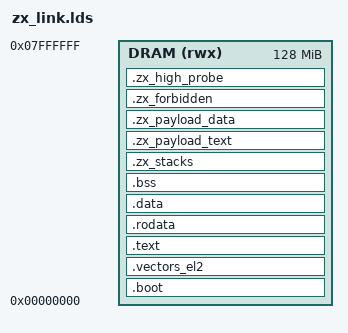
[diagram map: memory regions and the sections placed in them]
/***************************************************************************
 * Copyright (c) 2026 Eclipse ThreadX contributors
 *
 * This program and the accompanying materials are made available under the
 * terms of the MIT License which is available at
 * https://opensource.org/licenses/MIT.
 *
 * AI Disclosure: This file was largely AI-generated by Claude Code (Opus 5).
 * The AI-generated portions may be considered public domain (CC0-1.0)
 * and not subject to the project's licence. The human contributor has
 * reviewed and verified that the code is correct.
 *
 * SPDX-License-Identifier: MIT and CC0-1.0
 **************************************************************************/

/* Link map for the ZoneX stage-2 probe on the Armv8-R AEM FVP (BaseR).
 *
 * The BaseR memory map is the Base platform map with its two 2 GB halves
 * swapped: Base DRAM at 0x80000000 appears at 0x00000000 here, and the
 * 0x80000000-0xFFFFFFFF half holds peripherals and is execute-never in the
 * background map.  Code must therefore be linked into low DRAM; linking at
 * 0x80000000 produces a silent fault loop with no output.
 *
 * WHAT MAKES THIS SCRIPT DIFFERENT FROM AN ORDINARY BARE-METAL ONE
 *
 * Four areas below are not merely aligned but SIZED to whole 64-byte
 * granules, because each one is a stage-2 MPU region and PMSAv8-R has a
 * 64-byte granule with an inclusive limit:
 *
 *   .zx_payload_text   region 0, the payload's code
 *   .zx_payload_data   region 1, the payload's data
 *   .zx_forbidden      NO REGION AT ALL -- the whole point
 *   .zx_high_probe     region 16, the high-region experiment
 *
 * .zx_forbidden is placed IMMEDIATELY AFTER .zx_payload_data, adjacent by
 * construction.  An ungranted address far away from every grant proves only
 * that unmapped memory faults; the defect class worth catching is a region
 * whose limit or base is out by one granule, and only an adjacent hole
 * catches that.  Do not move it, and do not let anything land between it and
 * the payload's data.
 *
 * .zx_high_probe is placed after the hole rather than beside the payload,
 * because two enabled regions matching one address is CONSTRAINED
 * UNPREDICTABLE and aborts on the S32Z280.  Keeping region 16's granule well
 * clear of regions 0 and 1 makes the disjointness visible in the map file.
 *
 A NOTE ON ALIGN, because the two spellings are not equivalent
 *
 * Every ALIGN below is written AFTER the colon, which is the section's
 * ALIGNMENT.  Written before the colon it would be the section's ADDRESS,
 * evaluated from a location counter that starts at zero -- and it silently
 * overrides "> DRAM".  On this target that happens to be harmless because
 * DRAM starts at 0x00000000, which is precisely what makes it a trap: the
 * same script shape moved to the S32Z280, whose code SRAM starts at
 * 0x79900000, fails the link with "not within region" or, worse, places
 * sections somewhere plausible.  Keep both scripts in the safe form so that
 * neither teaches the wrong one.
 *
 * ZoneX's OWN code, data, bss and stack are covered by no region at all.
 * That is decision D2, not an oversight: with HSCTLR.BR=1 EL2's own accesses
 * fall back to the background map, while EL0/EL1 accesses that hit no region
 * fault regardless of BR -- so the hypervisor costs no region and is
 * protected from the payload precisely by not being mapped.
 */

ENTRY(_start)

__zx_hyp_stack_size = 0x1000;

MEMORY
{
    DRAM (rwx) : ORIGIN = 0x00000000, LENGTH = 0x08000000    /* 128 MB */
}

SECTIONS
{
    . = ALIGN(64);

    /* .text.boot first, so _start is at the front of the image.  It does not
       have to be at a fixed address on this target -- the model takes the
       entry point from the ELF -- but keeping the same section order as the
       silicon script, where it does, means one layout to reason about.  */

    .boot :
    {
        KEEP(*(.text.boot))
    } > DRAM

    .vectors_el2 :
    {
        KEEP(*(.vectors_el2))
    } > DRAM

    .text :
    {
        *(.text*)
        *(.glue_7)
        *(.glue_7t)
    } > DRAM

    .rodata :
    {
        . = ALIGN(4);
        *(.rodata*)
        . = ALIGN(4);
    } > DRAM

    .data : ALIGN(64)
    {
        __zx_data_start = .;
        *(.data*)
        . = ALIGN(4);
        __zx_data_end = .;
    } > DRAM

    .bss (NOLOAD) : ALIGN(64)
    {
        __zx_bss_start = .;
        *(.bss*)
        *(COMMON)
        . = ALIGN(4);
        __zx_bss_end = .;
    } > DRAM

    /* The hypervisor's Hyp-mode stack.  SP must stay 8-byte aligned
       (AAPCS), so the area is aligned before its top symbol is taken.  */

    .zx_stacks (NOLOAD) :
    {
        . = ALIGN(8);
        . = . + __zx_hyp_stack_size;
        __zx_hyp_stack_top = .;
    } > DRAM

    /* ------------------------------------------------------------------
       The partition areas.  Everything below is granule-aligned and
       granule-sized, and the ORDER of the last three is load-bearing.
       ------------------------------------------------------------------ */

    .zx_payload_text : ALIGN(64)
    {
        __zx_payload_code_start = .;
        KEEP(*(.zx_payload_text))
        . = ALIGN(64);
        __zx_payload_code_end = .;
    } > DRAM

    .zx_payload_data : ALIGN(64)
    {
        __zx_payload_data_start = .;
        KEEP(*(.zx_payload_data))
        . = ALIGN(64);
        __zx_payload_data_end = .;
    } > DRAM

    /* One granule, covered by NO region.  Adjacent to the payload's data by
       construction -- see the header.  */

    .zx_forbidden (NOLOAD) : ALIGN(64)
    {
        __zx_forbidden_start = .;
        . = . + 64;
        __zx_forbidden_end = .;
    } > DRAM

    .zx_high_probe : ALIGN(64)
    {
        __zx_high_probe_start = .;
        KEEP(*(.zx_high_probe))
        . = ALIGN(64);
        __zx_high_probe_end = .;
    } > DRAM

    . = ALIGN(8);
    _end = .;
    PROVIDE(end = .);

    /* Assert the geometry the region programming depends on, so that a
       layout mistake fails the LINK rather than the run.  A region whose
       base is under-aligned does not fault: its low bits land on SH, AP and
       XN and silently change the region's attributes, which is the single
       hardest failure in this architecture to see.  */

    ASSERT((__zx_payload_code_start & 63) == 0,
           "payload code region base is not 64-byte aligned")
    ASSERT((__zx_payload_code_end & 63) == 0,
           "payload code region is not a whole number of granules")
    ASSERT((__zx_payload_data_start & 63) == 0,
           "payload data region base is not 64-byte aligned")
    ASSERT((__zx_payload_data_end & 63) == 0,
           "payload data region is not a whole number of granules")
    ASSERT(__zx_forbidden_start == __zx_payload_data_end,
           "the ungranted granule is NOT adjacent to the payload's data region")
    ASSERT((__zx_high_probe_start & 63) == 0,
           "the high-probe region base is not 64-byte aligned")
    ASSERT(__zx_high_probe_start >= __zx_forbidden_end,
           "the high-probe region overlaps the ungranted granule")
}
